VERSION "1.0"

NS_ :

BS_:

BU_: VCU GATEWAY

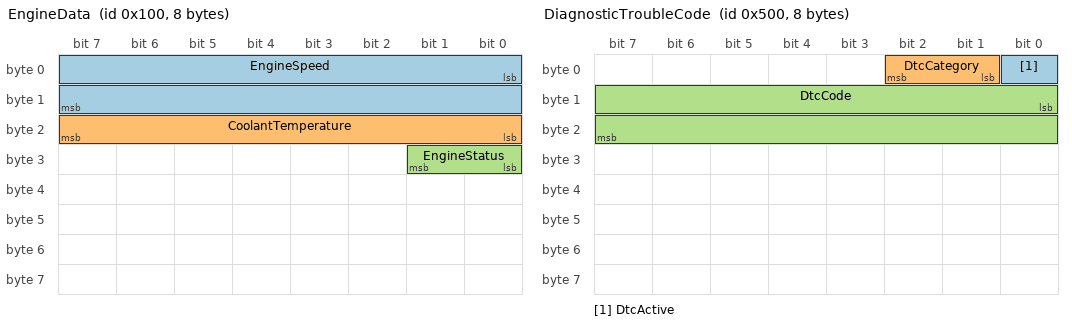
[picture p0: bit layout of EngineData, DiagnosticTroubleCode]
BO_ 256 EngineData: 8 VCU
 SG_ EngineSpeed : 0|16@1+ (0.25,0) [0|16383.75] "rpm" GATEWAY
 SG_ CoolantTemperature : 16|8@1+ (1,-40) [-40|215] "degC" GATEWAY
 SG_ EngineStatus : 24|2@1+ (1,0) [0|3] "" GATEWAY

BO_ 512 VehicleDynamics: 8 VCU
 SG_ VehicleSpeed : 0|16@1+ (0.01,0) [0|655.35] "km/h" GATEWAY
 SG_ FuelLevel : 16|8@1+ (0.4,0) [0|100] "%" GATEWAY

BO_ 768 BatteryStatus: 8 VCU
 SG_ BatteryVoltage : 0|16@1+ (0.001,0) [0|65.535] "V" GATEWAY

BO_ 1024 GnssPosition: 8 VCU
 SG_ Latitude : 0|32@1- (1E-007,0) [-90|90] "deg" GATEWAY
 SG_ Longitude : 32|32@1- (1E-007,0) [-180|180] "deg" GATEWAY

BO_ 1280 DiagnosticTroubleCode: 8 VCU
 SG_ DtcActive : 0|1@1+ (1,0) [0|1] "" GATEWAY
 SG_ DtcCategory : 1|2@1+ (1,0) [0|3] "" GATEWAY
 SG_ DtcCode : 8|16@1+ (1,0) [0|65535] "" GATEWAY

CM_ BO_ 256 "Engine speed, coolant temperature and engine state from the engine ECU.";
CM_ BO_ 512 "Vehicle speed and fuel level.";
CM_ BO_ 768 "Board net voltage.";
CM_ BO_ 1024 "GNSS position, WGS84, 1e-7 degree resolution.";
CM_ BO_ 1280 "Highest-priority active diagnostic trouble code.";
CM_ SG_ 1280 DtcCode "Four hex digits of the DTC, e.g. 0x0217 for P0217.";

BA_DEF_ BO_ "GenMsgCycleTime" INT 0 65535;
BA_DEF_DEF_ "GenMsgCycleTime" 0;
BA_ "GenMsgCycleTime" BO_ 256 100;
BA_ "GenMsgCycleTime" BO_ 512 100;
BA_ "GenMsgCycleTime" BO_ 768 1000;
BA_ "GenMsgCycleTime" BO_ 1024 1000;
BA_ "GenMsgCycleTime" BO_ 1280 1000;

VAL_ 256 EngineStatus 3 "FAULT" 2 "RUNNING" 1 "IDLE" 0 "OFF" ;
VAL_ 1280 DtcCategory 3 "U" 2 "B" 1 "C" 0 "P" ;
